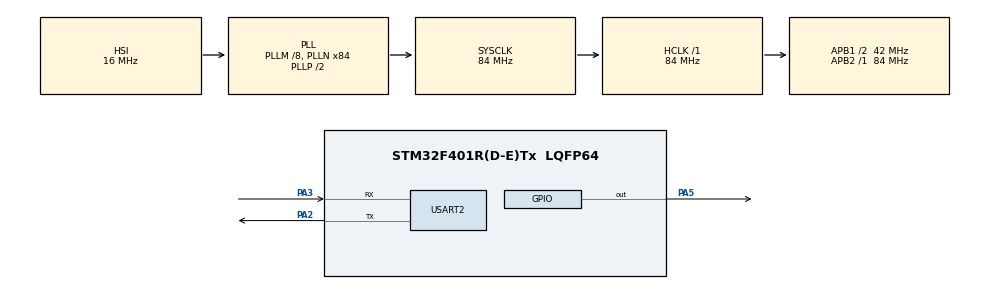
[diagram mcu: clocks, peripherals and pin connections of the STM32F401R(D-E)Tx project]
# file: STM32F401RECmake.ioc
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Mcu.Family=STM32F4
Mcu.Name=STM32F401R(D-E)Tx
Mcu.Package=LQFP64
NVIC.PriorityGroup=NVIC_PRIORITYGROUP_4
NVIC.USART2_IRQn=true\:0\:0\:false\:false\:true\:true\:true\:true
PA13.Mode=Serial_Wire
PA13.Signal=SYS_JTMS-SWDIO
PA14.Mode=Serial_Wire
PA14.Signal=SYS_JTCK-SWCLK
PA2.Mode=Asynchronous
PA2.Signal=USART2_TX
PA3.Mode=Asynchronous
PA3.Signal=USART2_RX
PA5.Signal=GPIO_Output
PH0\ -\ OSC_IN.Mode=HSE-External-Oscillator
PH0\ -\ OSC_IN.Signal=RCC_OSC_IN
PH1\ -\ OSC_OUT.Mode=HSE-External-Oscillator
PH1\ -\ OSC_OUT.Signal=RCC_OSC_OUT
ProjectManager.HeapSize=0x200
ProjectManager.StackSize=0x400
ProjectManager.TargetToolchain=CMake
RCC.48MHZClocksFreq_Value=42000000
RCC.AHBFreq_Value=84000000
RCC.APB1CLKDivider=RCC_HCLK_DIV2
RCC.APB1Freq_Value=42000000
RCC.APB1TimFreq_Value=84000000
RCC.APB2Freq_Value=84000000
RCC.APB2TimFreq_Value=84000000
RCC.CortexFreq_Value=84000000
RCC.HCLKFreq_Value=84000000
RCC.HSE_VALUE=8000000
RCC.HSI_VALUE=16000000
RCC.LSE_VALUE=32768
RCC.PLLM=8
RCC.PLLN=84
RCC.SYSCLKFreq_VALUE=84000000
RCC.SYSCLKSource=RCC_SYSCLKSOURCE_PLLCLK
RCC.VCOOutputFreq_Value=168000000
TIM3.Prescaler=84-1
USART2.VirtualMode=VM_ASYNC
VP_TIM3_VS_ClockSourceINT.Mode=Internal
board=custom

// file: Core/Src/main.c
/* USER CODE BEGIN Header */
/**
  ******************************************************************************
  * @file           : main.c
  * @brief          : Main program body
  ******************************************************************************
  * @attention
  *
  * Copyright (c) 2026 STMicroelectronics.
  * All rights reserved.
  *
  * This software is licensed under terms that can be found in the LICENSE file
  * in the root directory of this software component.
  * If no LICENSE file comes with this software, it is provided AS-IS.
  *
  ******************************************************************************
  */
/* USER CODE END Header */
#include "main.h"
#include "stm32f4xx_hal.h"
#include "tim.h"
#include "usart.h"
#include "gpio.h"

/* USER CODE BEGIN PTD */
#include "../../ports_and_adapters/application/inc/sensor_application.h"
#include "../../ports_and_adapters/application/inc/comm_application.h"

#include "../../ports_and_adapters/composition/sensor/inc/sensor_composition.h"
#include "../../ports_and_adapters/composition/comm/inc/comm_composition.h"

//extern uint8_t temperatura, humedad;
/* USER CODE END PTD */

void SystemClock_Config(void);

int main(void)
{

  /* USER CODE BEGIN 1 */

  Sensor_Application sensor_application;
  Comm_Application comm_application;
  /* USER CODE END 1 */

  /* MCU Configuration--------------------------------------------------------*/

  /* Reset of all peripherals, Initializes the Flash interface and the Systick. */
  HAL_Init();

  /* Configure the system clock */
  SystemClock_Config();

  /* Initialize all configured peripherals */
  MX_GPIO_Init();
  MX_USART2_UART_Init();
  MX_TIM3_Init();

  /* Infinite loop */
  /* USER CODE BEGIN WHILE */
  HAL_TIM_Base_Start(&htim3);
  /*
   * Composition Root: aquí se entregan explícitamente los recursos HAL.
   * Esto evita que Application/Adapters/Drivers dependan de globals ocultos.
   */
  sensor_composition_init(&sensor_application, &htim3);
  comm_composition_init(&comm_application, &huart2);
  while (1)
  {
    TemperatureData data;
    TemperatureLevel temperature_level;
    SensorStatus sensor_status;
    CommStatus comm_status;
    /*
      * -----------------------------------------------------
      * Leer sensor
      * -----------------------------------------------------
      */
    sensor_status =
        sensor_application_read(
            &sensor_application,
            &data,
            &temperature_level
        );

    if (sensor_status == SENSOR_OK)
    {
        comm_status =
            comm_application_send_temperature(
                &comm_application,
                &data
            );
        /*
         * Por ahora no hacemos nada con comm_status.
         * Posteriormente podemos manejar el error.
         */
        (void)comm_status;
    }
    HAL_Delay(2000);
    /* USER CODE END WHILE */
  }
}

void SystemClock_Config(void)
{
  RCC_OscInitTypeDef RCC_OscInitStruct = {0};
  RCC_ClkInitTypeDef RCC_ClkInitStruct = {0};

  /** Configure the main internal regulator output voltage
  */
  __HAL_RCC_PWR_CLK_ENABLE();
  __HAL_PWR_VOLTAGESCALING_CONFIG(PWR_REGULATOR_VOLTAGE_SCALE2);

  /** Initializes the RCC Oscillators according to the specified parameters
  * in the RCC_OscInitTypeDef structure.
  */
  RCC_OscInitStruct.OscillatorType = RCC_OSCILLATORTYPE_HSI;
  RCC_OscInitStruct.HSIState = RCC_HSI_ON;
  RCC_OscInitStruct.HSICalibrationValue = RCC_HSICALIBRATION_DEFAULT;
  RCC_OscInitStruct.PLL.PLLState = RCC_PLL_ON;
  RCC_OscInitStruct.PLL.PLLSource = RCC_PLLSOURCE_HSI;
  RCC_OscInitStruct.PLL.PLLM = 8;
  RCC_OscInitStruct.PLL.PLLN = 84;
  RCC_OscInitStruct.PLL.PLLP = RCC_PLLP_DIV2;
  RCC_OscInitStruct.PLL.PLLQ = 4;
  if (HAL_RCC_OscConfig(&RCC_OscInitStruct) != HAL_OK)
  {
    Error_Handler();
  }

  /** Initializes the CPU, AHB and APB buses clocks
  */
  RCC_ClkInitStruct.ClockType = RCC_CLOCKTYPE_HCLK|RCC_CLOCKTYPE_SYSCLK
                              |RCC_CLOCKTYPE_PCLK1|RCC_CLOCKTYPE_PCLK2;
  RCC_ClkInitStruct.SYSCLKSource = RCC_SYSCLKSOURCE_PLLCLK;
  RCC_ClkInitStruct.AHBCLKDivider = RCC_SYSCLK_DIV1;
  RCC_ClkInitStruct.APB1CLKDivider = RCC_HCLK_DIV2;
  RCC_ClkInitStruct.APB2CLKDivider = RCC_HCLK_DIV1;

  if (HAL_RCC_ClockConfig(&RCC_ClkInitStruct, FLASH_LATENCY_2) != HAL_OK)
  {
    Error_Handler();
  }
}

void Error_Handler(void)
{
  __disable_irq();
  while (1)
  {
  }
}
